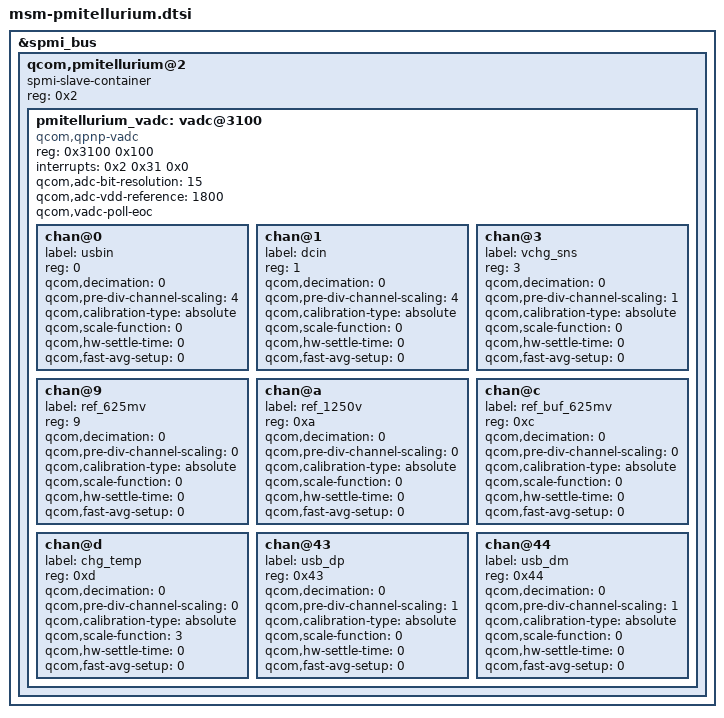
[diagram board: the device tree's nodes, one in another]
/* Copyright (c) 2015, The Linux Foundation. All rights reserved.
 *
 * This program is free software; you can redistribute it and/or modify
 * it under the terms of the GNU General Public License version 2 and
 * only version 2 as published by the Free Software Foundation.
 *
 * This program is distributed in the hope that it will be useful,
 * but WITHOUT ANY WARRANTY; without even the implied warranty of
 * MERCHANTABILITY or FITNESS FOR A PARTICULAR PURPOSE.  See the
 * GNU General Public License for more details.
 */

&spmi_bus {

	qcom,pmitellurium@2 {
		spmi-slave-container;
		reg = <0x2>;
		#address-cells = <1>;
		#size-cells = <1>;

		pmitellurium_vadc: vadc@3100 {
			compatible = "qcom,qpnp-vadc";
			reg = <0x3100 0x100>;
			#address-cells = <1>;
			#size-cells = <0>;
			interrupts = <0x2 0x31 0x0>;
			interrupt-names = "eoc-int-en-set";
			qcom,adc-bit-resolution = <15>;
			qcom,adc-vdd-reference = <1800>;
			qcom,vadc-poll-eoc;

			chan@0 {
				label = "usbin";
				reg = <0>;
				qcom,decimation = <0>;
				qcom,pre-div-channel-scaling = <4>;
				qcom,calibration-type = "absolute";
				qcom,scale-function = <0>;
				qcom,hw-settle-time = <0>;
				qcom,fast-avg-setup = <0>;
			};

			chan@1 {
				label = "dcin";
				reg = <1>;
				qcom,decimation = <0>;
				qcom,pre-div-channel-scaling = <4>;
				qcom,calibration-type = "absolute";
				qcom,scale-function = <0>;
				qcom,hw-settle-time = <0>;
				qcom,fast-avg-setup = <0>;
			};

			chan@3 {
				label = "vchg_sns";
				reg = <3>;
				qcom,decimation = <0>;
				qcom,pre-div-channel-scaling = <1>;
				qcom,calibration-type = "absolute";
				qcom,scale-function = <0>;
				qcom,hw-settle-time = <0>;
				qcom,fast-avg-setup = <0>;
			};

			chan@9 {
				label = "ref_625mv";
				reg = <9>;
				qcom,decimation = <0>;
				qcom,pre-div-channel-scaling = <0>;
				qcom,calibration-type = "absolute";
				qcom,scale-function = <0>;
				qcom,hw-settle-time = <0>;
				qcom,fast-avg-setup = <0>;
			};

			chan@a {
				label = "ref_1250v";
				reg = <0xa>;
				qcom,decimation = <0>;
				qcom,pre-div-channel-scaling = <0>;
				qcom,calibration-type = "absolute";
				qcom,scale-function = <0>;
				qcom,hw-settle-time = <0>;
				qcom,fast-avg-setup = <0>;
			};

			chan@c {
				label = "ref_buf_625mv";
				reg = <0xc>;
				qcom,decimation = <0>;
				qcom,pre-div-channel-scaling = <0>;
				qcom,calibration-type = "absolute";
				qcom,scale-function = <0>;
				qcom,hw-settle-time = <0>;
				qcom,fast-avg-setup = <0>;
			};

			chan@d {
				label = "chg_temp";
				reg = <0xd>;
				qcom,decimation = <0>;
				qcom,pre-div-channel-scaling = <0>;
				qcom,calibration-type = "absolute";
				qcom,scale-function = <3>;
				qcom,hw-settle-time = <0>;
				qcom,fast-avg-setup = <0>;
			};

			chan@43 {
				label = "usb_dp";
				reg = <0x43>;
				qcom,decimation = <0>;
				qcom,pre-div-channel-scaling = <1>;
				qcom,calibration-type = "absolute";
				qcom,scale-function = <0>;
				qcom,hw-settle-time = <0>;
				qcom,fast-avg-setup = <0>;
			};

			chan@44 {
				label = "usb_dm";
				reg = <0x44>;
				qcom,decimation = <0>;
				qcom,pre-div-channel-scaling = <1>;
				qcom,calibration-type = "absolute";
				qcom,scale-function = <0>;
				qcom,hw-settle-time = <0>;
				qcom,fast-avg-setup = <0>;
			};
		};
	};
};
